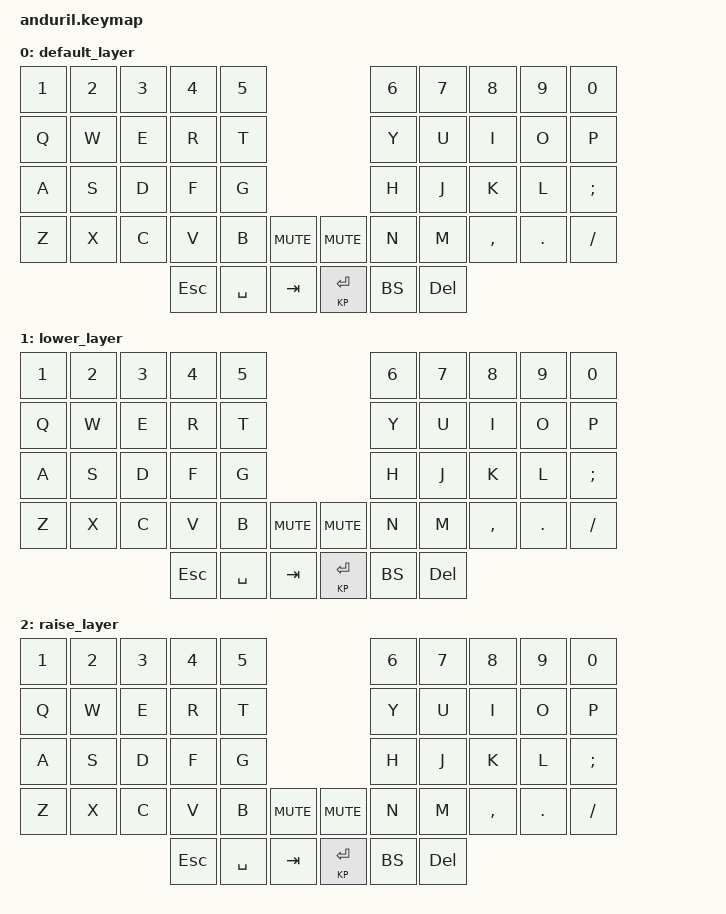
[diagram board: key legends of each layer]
/*
 * Copyright (c) 2020 The ZMK Contributors
 *
 * SPDX-License-Identifier: MIT
 */

#include <behaviors.dtsi>
#include <dt-bindings/zmk/bt.h>
#include <dt-bindings/zmk/ext_power.h>
#include <dt-bindings/zmk/keys.h>
#include <dt-bindings/zmk/rgb.h>

#define BASE 0
#define LOWER 1
#define RAISE 2
#define ADJUST 3

/ {
    // Activate ADJUST layer by pressing raise and lower

    conditional_layers {
        compatible = "zmk,conditional-layers";

        adjust_layer {
            if-layers = <LOWER RAISE>;
            then-layer = <ADJUST>;
        };
    };

    keymap {
        compatible = "zmk,keymap";

        default_layer {
            // ------------------------------------------------------------------------------------------------------------
            // |  1  |  2  |  3   |  4   |  5   |                   |  6   |  7    |  8    |  9   |   0   |
            // |  Q  |  W  |  E   |  R   |  T   |                   |  Y   |  U    |  I    |  O   |   P   |
            // |  A  |  S  |  D   |  F   |  G   |                   |  H   |  J    |  K    |  L   |   ;   |
            // |  Z  |  X  |  C   |  V   |  B   | C/A/D|    | MUTE  |  N   |  M    |  ,    |  .   |   /   |
            //                    | ESC  | SPACE| TAB  |    | ENTER |  BS  |  DEL  | 
 
            bindings = <
&kp N1  &kp N2    &kp N3    &kp N4     &kp N5                              &kp N6     &kp N7     &kp N8     &kp N9    &kp N0  
&kp Q   &kp W     &kp E     &kp R      &kp T                               &kp Y      &kp U      &kp I      &kp O     &kp P  
&kp A   &kp S     &kp D     &kp F      &kp G                               &kp H      &kp J      &kp K      &kp L     &kp SEMI 
&kp Z   &kp X     &kp C     &kp V      &kp B      &kp C_MUTE    & C_MUTE   &kp N      &kp M      &kp COMMA  &kp DOT   &kp FSLH  
                            &kp ESC    &kp SPACE  &kp TAB       &KP ENTER  &kp BS    &kp DEL 
            >;

            sensor-bindings = <&inc_dec_kp C_VOL_UP C_VOL_DN &inc_dec_kp PG_UP PG_DN>;
        };

        lower_layer {
            // ------------------------------------------------------------------------------------------------------------
            // |  1  |  2  |  3   |  4   |  5   |                   |  6   |  7    |  8    |  9   |   0   |
            // |  Q  |  W  |  E   |  R   |  T   |                   |  Y   |  U    |  I    |  O   |   P   |
            // |  A  |  S  |  D   |  F   |  G   |                   |  H   |  J    |  K    |  L   |   ;   |
            // |  Z  |  X  |  C   |  V   |  B   | C/A/D|    | MUTE  |  N   |  M    |  ,    |  .   |   /   |
            //                    | ESC  | SPACE| TAB  |    | ENTER |  BS  |  DEL  | 
 
            bindings = <
&kp N1  &kp N2    &kp N3    &kp N4     &kp N5                              &kp N6     &kp N7     &kp N8     &kp N9    &kp N0  
&kp Q   &kp W     &kp E     &kp R      &kp T                               &kp Y      &kp U      &kp I      &kp O     &kp P  
&kp A   &kp S     &kp D     &kp F      &kp G                               &kp H      &kp J      &kp K      &kp L     &kp SEMI 
&kp Z   &kp X     &kp C     &kp V      &kp B      &kp C_MUTE    & C_MUTE   &kp N      &kp M      &kp COMMA  &kp DOT   &kp FSLH  
                            &kp ESC    &kp SPACE  &kp TAB       &KP ENTER  &kp BS    &kp DEL 
            >;

            sensor-bindings = <&inc_dec_kp C_VOL_UP C_VOL_DN &inc_dec_kp PG_UP PG_DN>;
        };

        raise_layer {
            // ------------------------------------------------------------------------------------------------------------
            // |  1  |  2  |  3   |  4   |  5   |                   |  6   |  7    |  8    |  9   |   0   |
            // |  Q  |  W  |  E   |  R   |  T   |                   |  Y   |  U    |  I    |  O   |   P   |
            // |  A  |  S  |  D   |  F   |  G   |                   |  H   |  J    |  K    |  L   |   ;   |
            // |  Z  |  X  |  C   |  V   |  B   | C/A/D|    | MUTE  |  N   |  M    |  ,    |  .   |   /   |
            //                    | ESC  | SPACE| TAB  |    | ENTER |  BS  |  DEL  | 
 
            bindings = <
&kp N1  &kp N2    &kp N3    &kp N4     &kp N5                              &kp N6     &kp N7     &kp N8     &kp N9    &kp N0  
&kp Q   &kp W     &kp E     &kp R      &kp T                               &kp Y      &kp U      &kp I      &kp O     &kp P  
&kp A   &kp S     &kp D     &kp F      &kp G                               &kp H      &kp J      &kp K      &kp L     &kp SEMI 
&kp Z   &kp X     &kp C     &kp V      &kp B      &kp C_MUTE    & C_MUTE   &kp N      &kp M      &kp COMMA  &kp DOT   &kp FSLH  
                            &kp ESC    &kp SPACE  &kp TAB       &KP ENTER  &kp BS    &kp DEL 
            >;

            sensor-bindings = <&inc_dec_kp C_VOL_UP C_VOL_DN &inc_dec_kp PG_UP PG_DN>;
        };
    };
};

